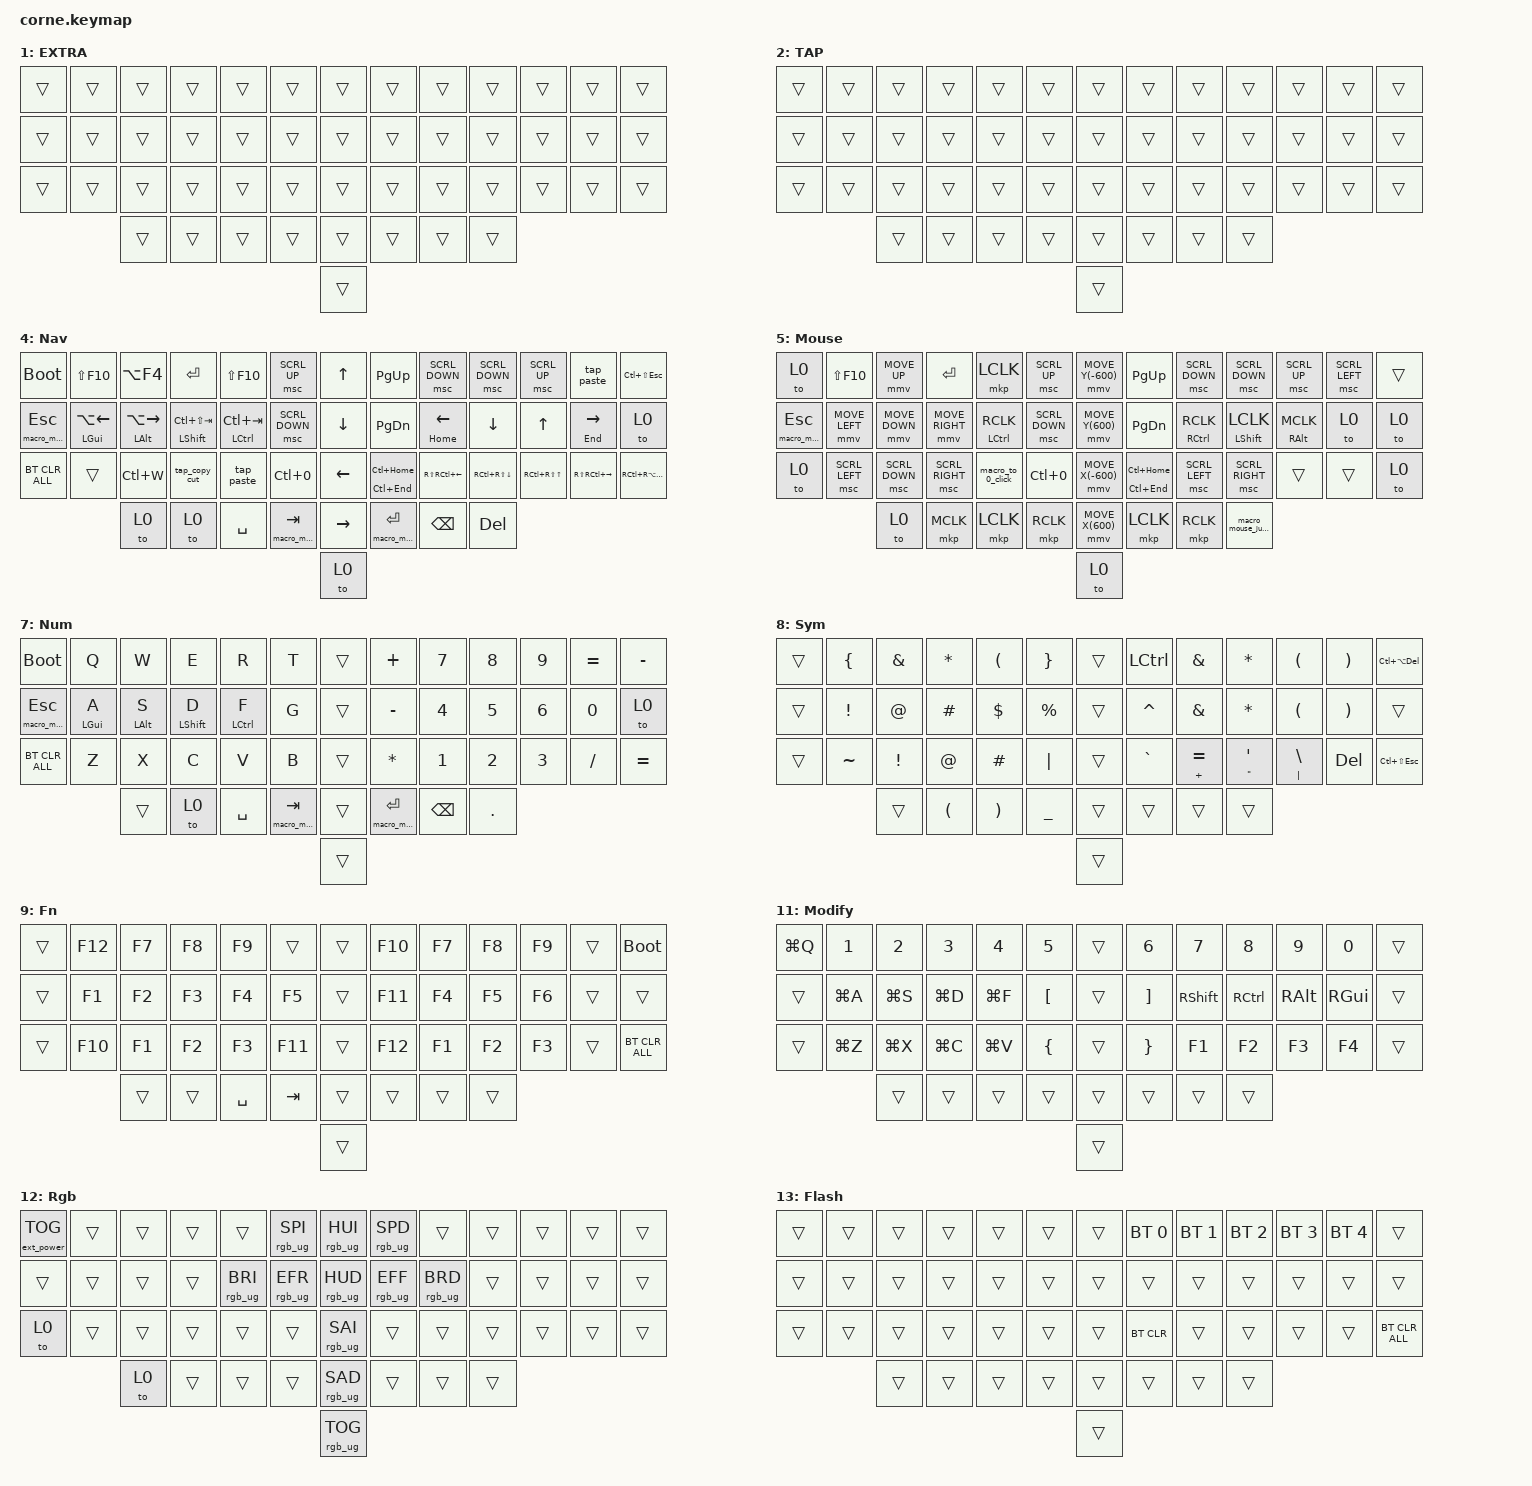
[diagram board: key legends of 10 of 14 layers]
#define ZMK_POINTING_DEFAULT_MOVE_VAL 1200  // 600
#define ZMK_POINTING_DEFAULT_SCRL_VAL 35    // 10

#include <dt-bindings/zmk/outputs.h>
#include <behaviors/num_word.dtsi> // Requires auto-layer module.
#include <input/processors.dtsi>
#include <zephyr/dt-bindings/input/input-event-codes.h>
#include "zmk-helpers/helper.h"
#include <behaviors.dtsi>
#include <dt-bindings/zmk/bt.h>
#include <dt-bindings/zmk/ext_power.h>
#include <dt-bindings/zmk/keys.h>
#include <dt-bindings/zmk/pointing.h>
#include <dt-bindings/zmk/rgb.h>

// Special Aliases

#define ___ &trans
#define MEH     LC(LS(LALT))
#define HYPER   LC(LS(LA(LGUI)))
#define U_RDO   LC(Y)
#define U_PST   LC(V)
#define U_PST_P LS(LC(V))
#define U_CPY   LC(C)
#define U_CUT   LC(X)
#define U_UND   LC(Z)

// Switch program by taskbar position

#define T_1 &kp LC(LG(N1))
#define T_2 &kp LG(LC(N2))
#define T_3 &kp LG(LC(N3))
#define T_4 &kp LG(LC(N4))
#define T_5 &kp LG(LC(N5))
#define T_6 &kp LG(LC(N6))
#define T_7 &kp LG(LC(N7))
#define T_8 &kp LG(LC(N8))
#define T_9 &kp LG(LC(N9))
#define T_0 &kp LG(LC(N0))

// Switch monitor layout

#define M_1 &kp LG(LC(LA(N1)))
#define M_2 &kp LG(LC(LA(N2)))
#define M_3 &kp LG(LC(LA(N3)))
#define M_4 &kp LG(LC(LA(N4)))
#define M_5 &kp LG(LC(LA(N5)))
#define M_6 &kp LG(LC(LA(N6)))
#define M_7 &kp LG(LC(LA(N7)))
#define M_8 &kp LG(LC(LA(N8)))
#define M_9 &kp LG(LC(LA(N9)))
#define M_0 &kp LG(LC(LA(N0)))

/* Global defaults */

#define QUICK_TAP_MS 175

/*



SENSIBLE_LAYER_LIST?

#define DEF 0
#define NAV 1
#define FN 2
#define NUM 3
#define SYS 4
#define MOUSE 5


*/

/ {
    zip_scroll_scaler: zip_scroll_scaler {
        compatible = "zmk,input-processor-scaler";
        #input-processor-cells = <2>;
        type = <INPUT_EV_REL>;
        codes = <INPUT_REL_WHEEL INPUT_REL_HWHEEL>;
        track-remainders;
    };
};

&mmv_input_listener { input-processors = <&zip_xy_scaler 2 1>; };

&msc_input_listener { input-processors = <&zip_scroll_scaler 2 1>; };

&msc {
    acceleration-exponent = <0>;      // 0
    time-to-max-speed-ms = <0>;       // 300
    delay-ms = <0>;                   // 0
};

&mmv {
    time-to-max-speed-ms = <500>;
    acceleration-exponent = <3>;
};

&inc_dec_kp {
    tap-ms = <0>;
    bindings = <&kp>, <&kp>;
};

&sk { quick-release; };

&sl {
    ignore-modifiers;          // allow chording sticky mods & layers
};

&lt {
    flavor = "balanced";
    tapping-term-ms = <200>;
    quick-tap-ms = <QUICK_TAP_MS>;
};

/ {
    macros {
        macro_dot_shift: macro_dot_shift {
            compatible = "zmk,behavior-macro";
            #binding-cells = <0>;
            bindings = <&kp DOT &kp SPACE &sk LSHFT>;
            label = "MACRO_DOT_SHIFT";
        };

        macro_mouse_jump: to_mouse {
            compatible = "zmk,behavior-macro";
            #binding-cells = <0>;
            bindings = <&kp LS(RG(D)) &to 5>;
            label = "TO_MOUSE";
        };

        macro_to_0_click: macro_to_0_click {
            compatible = "zmk,behavior-macro";
            #binding-cells = <0>;
            bindings = <&mkp RCLK &to 0>;
            label = "MACRO_TO_0_CLICK";
        };

        macro_sel_word: macro_sel_word {
            compatible = "zmk,behavior-macro";
            #binding-cells = <0>;
            bindings = <&kp LC(LEFT) &kp LC(LS(RIGHT))>;
            label = "MACRO_SEL_WORD";
        };

        macro_sel_line: macro_sel_line {
            compatible = "zmk,behavior-macro";
            #binding-cells = <0>;
            bindings = <&kp HOME &kp LS(END)>;
            label = "MACRO_SEL_LINE";
        };

        macro_win_sleep: macro_win_sleep {
            compatible = "zmk,behavior-macro";
            #binding-cells = <0>;
            bindings = <&kp LG(X) &kp U &kp S>;
            label = "MACRO_WIN_SLEEP";
            wait-ms = <500>;
            tap-ms = <5>;
        };

        macro_swapper: macro_swapper {
            compatible = "zmk,behavior-macro";
            #binding-cells = <0>;
            bindings =
                <&macro_press>,
                <&kp LALT>,
                <&macro_tap>,
                <&kp TAB>,
                <&macro_release>,
                <&kp LALT>;

            label = "MACRO_SWAPPER";
        };

        double_click: double_click {
            compatible = "zmk,behavior-macro";
            #binding-cells = <0>;
            bindings = <&mkp RCLK &mkp RCLK>;
            label = "DOUBLE_CLICK";
        };

        macro_mouse_jiggle: mouse_jiggle {
            compatible = "zmk,behavior-macro";
            #binding-cells = <0>;
            bindings = <&to 0 &mmv MOVE_UP &mmv MOVE_LEFT &mmv MOVE_DOWN &mmv MOVE_RIGHT>;
            label = "MOUSE_JIGGLE";
        };
    };

    behaviors {
        hml: homerow_mods_left {
            compatible = "zmk,behavior-hold-tap";
            label = "HOMEROW_MODS_LEFT";
            bindings = <&kp>, <&kp>;

            #binding-cells = <2>;
            tapping-term-ms = <175>;
            quick-tap-ms = <150>;
            flavor = "balanced";
            require-prior-idle-ms = <0>;
            hold-trigger-key-positions = <21 22 23 41 20 7 8 33 34 35 36 37 38 25 24 11 12 10 9 44 45 46 14 40 42>;
        };

        hmr: homerow_mods_right {
            compatible = "zmk,behavior-hold-tap";
            label = "HOMEROW_MODS_RIGHT";
            bindings = <&kp>, <&kp>;

            #binding-cells = <2>;
            tapping-term-ms = <175>;
            quick-tap-ms = <150>;
            flavor = "balanced";
            require-prior-idle-ms = <0>;
            hold-trigger-key-positions = <14 15 16 17 0 1 13 26 27 28 29 30 31 5 2 3 4 18 23 45 46 44>;
        };

        ltq: ltq {
            compatible = "zmk,behavior-hold-tap";
            label = "LTQ";
            bindings = <&mo>, <&kp>;

            #binding-cells = <2>;
            tapping-term-ms = <175>;
            quick-tap-ms = <150>;
            flavor = "balanced";
            require-prior-idle-ms = <50>;
            hold-trigger-key-positions = <21 22 23 24 2 15 16 1>;
        };

        as: auto_shift {
            compatible = "zmk,behavior-hold-tap";
            label = "AUTO_SHIFT";
            bindings = <&kp>, <&kp>;

            #binding-cells = <2>;
            tapping-term-ms = <225>;
            quick-tap-ms = <175>;
            flavor = "tap-preferred";
            require-prior-idle-ms = <50>;
        };

        num_word: num_word {
            compatible = "zmk,behavior-auto-layer";
            #binding-cells = <1>;
            continue-list = <BSPC DEL KP_DOT DOT COMMA KP_PLUS PLUS KP_MINUS MINUS KP_MULTIPLY STAR KP_DIVIDE FSLH EQUAL>;
            ignore-numbers;
        };

        smart_num: smart_num {
            compatible = "zmk,behavior-hold-tap";
            label = "SMART_NUM";
            bindings = <&mo>, <&num_word>;

            #binding-cells = <2>;
            tapping-term-ms = <150>;
            flavor = "tap-preferred";
            hold-trigger-key-positions = <41>;
        };

        rgb_encoder: rgb_encoder {
            compatible = "zmk,behavior-sensor-rotate";
            label = "RGB_ENCODER";
            #sensor-binding-cells = <0>;
            bindings = <&rgb_ug RGB_BRI>, <&rgb_ug RGB_BRD>;

            tap-ms = <5>;
        };

        scroll_encoder: scroll_encoder {
            compatible = "zmk,behavior-sensor-rotate";
            #sensor-binding-cells = <0>;
            bindings = <&msc SCRL_UP>, <&msc SCRL_DOWN>;

            tap-ms = <5>;
            label = "scroll_encoder";
        };

        backspace_delete: backspace_delete {
            compatible = "zmk,behavior-mod-morph";
            #binding-cells = <0>;
            bindings = <&kp BACKSPACE>, <&kp DELETE>;

            mods = <(MOD_LSFT|MOD_RSFT)>;
            keep-mods = <(MOD_RSFT)>;
            label = "BACKSPACE_DELETE";
        };

        tap_dot_shift: tap_dot_shift {
            compatible = "zmk,behavior-tap-dance";
            label = "tap_dot_shift";
            #binding-cells = <0>;
            bindings = <&kp DOT>, <&macro_dot_shift>;

            tapping-term-ms = <250>;
        };

        c_tap_copy_cut: c_tap_copy_cut {
            compatible = "zmk,behavior-tap-dance";
            label = "C_TAP_COPY_CUT";
            #binding-cells = <0>;
            tapping-term-ms = <250>;
            bindings = <&kp C>, <&kp LC(C)>, <&kp LC(X)>;
        };

        sk_qr: sk_qr {
            compatible = "zmk,behavior-sticky-key";
            label = "SK_QR";
            bindings = <&sk>;
            #binding-cells = <1>;
            quick-release;
            release-after-ms = <900>;
        };

        morph_column: morph_column {
            compatible = "zmk,behavior-mod-morph";
            label = "MORPH_COLUMN";
            bindings = <&kp COLON>, <&kp SEMICOLON>;

            #binding-cells = <0>;
            mods = <(MOD_LSFT)>;
            keep-mods = <(MOD_LSFT)>;
        };

        ltq_mouse_column: ltq_mouse_column {
            compatible = "zmk,behavior-hold-tap";
            label = "LTQ_MOUSE_COLUMN";
            bindings = <&mo>, <&morph_column>;

            #binding-cells = <2>;
            flavor = "balanced";
            tapping-term-ms = <175>;
            quick-tap-ms = <150>;
            require-prior-idle-ms = <50>;
            hold-trigger-key-positions = <15 14 2 16 4 17 41 42 44 45 20>;
        };

        tap_quote_to_nav_mouse: tap_quote_to_nav_mouse {
            compatible = "zmk,behavior-tap-dance";
            label = "TAP_QUOTE_TO_NAV_MOUSE";
            #binding-cells = <0>;
            bindings = <&kp SQT>, <&to 4>, <&to 5>;

            tapping-term-ms = <150>;
        };

        dot_shift: dot_shift {
            compatible = "zmk,behavior-hold-tap";
            label = "DOT_SHIFT";
            bindings = <&macro_dot_shift>, <&kp>;

            #binding-cells = <2>;
            tapping-term-ms = <250>;
            quick-tap-ms = <200>;
            flavor = "tap-preferred";
            require-prior-idle-ms = <150>;
            hold-trigger-on-release;
        };

        hmr_clk: hmr_clk {
            compatible = "zmk,behavior-hold-tap";
            label = "HMR_CLK";
            bindings = <&hmr>, <&mkp>;

            #binding-cells = <2>;
            tapping-term-ms = <250>;
            quick-tap-ms = <200>;
            flavor = "tap-preferred";
            require-prior-idle-ms = <150>;
        };

        v_tap_paste: v_tap_paste {
            compatible = "zmk,behavior-tap-dance";
            label = "V_TAP_PASTE";
            #binding-cells = <0>;
            tapping-term-ms = <250>;
            bindings = <&kp V>, <&kp LC(V)>, <&kp LC(LS(V))>;
        };

        tap_paste: tap_paste {
            compatible = "zmk,behavior-tap-dance";
            label = "TAP_PASTE";
            #binding-cells = <0>;
            tapping-term-ms = <250>;
            bindings = <&kp LC(V)>, <&kp LC(LS(V))>;
        };

        tap_copy_cut: tap_copy_cut {
            compatible = "zmk,behavior-tap-dance";
            label = "TAP_COPY_CUT";
            #binding-cells = <0>;
            tapping-term-ms = <250>;
            bindings = <&kp LC(C)>, <&kp LC(X)>;
        };

        tap_dot_shift_capsword: tap_dot_shift_capsword {
            compatible = "zmk,behavior-tap-dance";
            label = "TAP_DOT_SHIFT_CAPSWORD";
            #binding-cells = <0>;
            tapping-term-ms = <250>;
            bindings = <&kp DOT>, <&macro_dot_shift>, <&caps_word>;
        };

        tap_key_repeat_lt: tap_key_repeat_lt {
            compatible = "zmk,behavior-hold-tap";
            label = "TAP_KEY_REPEAT_LT";
            #binding-cells = <2>;
            tapping-term-ms = <175>;
            quick-tap-ms = <150>;
            flavor = "balanced";
            require-prior-idle-ms = <50>;
            bindings = <&lt>, <&key_repeat>;
        };

        mod_to: mod_to {
            compatible = "zmk,behavior-hold-tap";
            label = "MOD_TO";
            bindings = <&to>, <&kp>;

            #binding-cells = <2>;
            tapping-term-ms = <225>;
            quick-tap-ms = <175>;
            flavor = "tap-preferred";
            require-prior-idle-ms = <50>;
        };

        mod_to0_mouse_jiggle: mod_to0_mouse_jiggle {
            compatible = "zmk,behavior-hold-tap";
            label = "MOD_TO0_MOUSE_JIGGLE";
            bindings = <&macro_mouse_jiggle>, <&kp>;

            #binding-cells = <2>;
            tapping-term-ms = <225>;
            quick-tap-ms = <175>;
            flavor = "tap-preferred";
            require-prior-idle-ms = <50>;
        };

        tap_flip_komorebic: tap_flip_komorebic {
            compatible = "zmk,behavior-tap-dance";
            label = "TAP_FLIP_KOMOREBIC";
            #binding-cells = <0>;
            tapping-term-ms = <200>;
            bindings = <&kp RS(RA(F17))>, <&kp RA(RS(F18))>, <&none>;
        };
    };

    combos {
        compatible = "zmk,combos";

        tap_copy_cut {
            bindings = <&tap_copy_cut>;
            key-positions = <28 29>;
        };

        tap_paste {
            bindings = <&tap_paste>;
            key-positions = <29 30>;
        };

        Enter_v2 {
            bindings = <&kp RET>;
            key-positions = <17 3>;
        };

        Undo {
            bindings = <&kp LC(Z)>;
            key-positions = <35 34>;
        };

        Redo {
            bindings = <&kp LS(LC(Z))>;
            key-positions = <35 36>;
        };

        ctrl_space {
            bindings = <&kp LC(SPACE)>;
            key-positions = <41 17>;
            timeout-ms = <30>;
            require-prior-idle-ms = <30>;
        };

        to_mouse {
            bindings = <&to 5>;
            key-positions = <24 23>;
        };

        f21 {
            bindings = <&kp F21>;
            key-positions = <23 22>;
        };

        macro_dot_shift {
            bindings = <&tap_dot_shift_capsword>;
            key-positions = <16 41>;
            layers = <0>;
        };

        to_0v2 {
            bindings = <&to 0>;
            key-positions = <42 41>;
        };

        to_0v1 {
            bindings = <&to 0>;
            key-positions = <18 17>;
        };

        to_ov3 {
            bindings = <&to 0>;
            key-positions = <44 45>;
        };

        Select_all {
            bindings = <&kp LC(A)>;
            key-positions = <27 28>;
        };
    };

    #define KEYS_L LT0 LT1 LT2 LT3 LT4 LT5 LM0 LM1 LM2 LM3 LM4 LM5 LB0 LB1 LB2 LB3 LB4 LB5  // left hand
#define KEYS_R RT0 RT1 RT2 RT3 RT4 RT5 RM0 RM1 RM2 RM3 RM4 RM5 RB0 RB1 RB2 RB3 RB4 RB5  // right hand
#define THUMBS LH2 LH1 LH0 RH0 RH1 RH2   // thumbs
    /*                42 KEY MATRIX with ENCODER and JOYSTICK / LAYOUT MAPPING

  ╭──────────────────────────────╮              ╭─────╮      ╭──────────────────────────────╮
  │ LT5  LT4  LT3  LT2  LT1  LT0 │          ╭───╯ JS0 ╰───╮  │ RT0  RT1  RT2  RT3  RT4  RT5 │
  │ LM5  LM4  LM3  LM2  LM1  LM0 │ ╭─────╮  │ JS1 JS2 JS3 │  │ RM0  RM1  RM2  RM3  RM4  RM5 │
  │ LB5  LB4  LB3  LB2  LB1  LB0 │ │ LEC │  ╰───╮ JS4 ╭───╯  │ RB0  RB1  RB2  RB3  RB4  RB5 │
  ╰──────────────╮ LH2  LH1  LH0 │ ╰─────╯      ╰─────╯      │ RH0  RH1  RH2 ╭──────────────╯
                 ╰───────────────╯                           ╰───────────────╯


#define MAKE_HRM(NAME, HOLD, TAP, TRIGGER_POS)                                 \
  ZMK_HOLD_TAP(

    NAME,
    bindings = <HOLD>, <TAP>;

    flavor = "balanced";
    tapping-term-ms = <280>;
    quick-tap-ms = <QUICK_TAP_MS>;
    require-prior-idle-ms = <150>;
    hold-trigger-on-release;
    hold-trigger-key-positions = <TRIGGER_POS>;

    )

MAKE_HRM(hmlx, &kp, &kp, KEYS_R THUMBS) // Left-hand HRMs.
    MAKE_HRM(hmrx, &kp, &kp, KEYS_L THUMBS) // Right-hand HRMs.

// Hack: Make HRM combos tap-only (cf, ZMK issue #544).
#define ZMK_COMBO_8(NAME, TAP, POS, LAYERS, COMBO_MS, IDLE_MS, HOLD, SIDE)     \
  MAKE_HRM(hm_combo_##NAME, &kp, TAP, SIDE THUMBS)                             \
  ZMK_COMBO_6(NAME, &hm_combo_##NAME HOLD 0, POS, LAYERS, COMBO_MS, IDLE_MS)


// Tap: num-word | double-tap: sticky num-layer | Hold: num-layer.
#define SMART_NUM &smart_num NUM 0
ZMK_HOLD_TAP(

    smart_num,
    bindings = <&mo>, <&num_dance>;

    flavor = "balanced";
    tapping-term-ms = <200>;
    quick-tap-ms = <QUICK_TAP_MS>;

    )
ZMK_TAP_DANCE(

    num_dance,
    bindings = <&num_word NUM>, <&sl NUM>;

    tapping-term-ms = <200>;

    )

*/

    keymap {
        compatible = "zmk,keymap";

        BASE {
            bindings = <
&ltq 12 GRAVE                   &as LS(F10) Q  &kp W            &as RET E          &as LS(F10) R        &kp T                  &kp UP_ARROW    &as PAGE_UP Y    &kp U             &kp I                   &kp O                    &kp P        &as RC(MINUS) MINUS
&mod_to0_mouse_jiggle 0 ESCAPE  &ltq 4 A       &hml LEFT_ALT S  &hml LEFT_SHIFT D  &hml LCTRL F         &hml LEFT_GUI G        &kp DOWN_ARROW  &as PAGE_DOWN H  &hmr RCTRL J      &hmr LEFT_SHIFT K       &hmr RIGHT_ALT L         &ltq 5 SEMI  &tap_quote_to_nav_mouse
&ltq 3 LA(TAB)                  &kp Z          &kp X            &kp C              &as LC(LA(LS(V))) V  &as LS(LA(LC(V))) B    &kp LEFT        &kp N            &kp M             &kp COMMA               &tap_dot_shift_capsword  &kp FSLH     &as RC(EQUAL) EQUAL
                                               &ltq 6 C_MUTE    &smart_num 7 7     &ltq 10 SPACE        &ltq 4 TAB             &kp RIGHT       &ltq 5 RET       &ltq 6 BACKSPACE  &tap_key_repeat_lt 9 9
                                                                                                                               &to 5
            >;

            label = "BASE";
            sensor-bindings = <&inc_dec_kp UP DOWN>;
        };

        EXTRA {
            bindings = <
&trans  &trans  &trans  &trans  &trans  &trans    &trans  &trans  &trans  &trans  &trans  &trans  &trans
&trans  &trans  &trans  &trans  &trans  &trans    &trans  &trans  &trans  &trans  &trans  &trans  &trans
&trans  &trans  &trans  &trans  &trans  &trans    &trans  &trans  &trans  &trans  &trans  &trans  &trans
                &trans  &trans  &trans  &trans    &trans  &trans  &trans  &trans
                                                  &trans
            >;

            label = "EXTRA";
        };

        TAP {
            bindings = <
&trans  &trans  &trans  &trans  &trans  &trans    &trans  &trans  &trans  &trans  &trans  &trans  &trans
&trans  &trans  &trans  &trans  &trans  &trans    &trans  &trans  &trans  &trans  &trans  &trans  &trans
&trans  &trans  &trans  &trans  &trans  &trans    &trans  &trans  &trans  &trans  &trans  &trans  &trans
                &trans  &trans  &trans  &trans    &trans  &trans  &trans  &trans
                                                  &trans
            >;

            label = "TAP";
        };

        BUTTON {
            bindings = <
&trans  &kp LS(LG(LC(LA(Q))))  &kp LA(F4)  &kp LG(LC(LA(E)))         &kp LC(F24)              &kp LS(LG(LC(LA(T))))             &trans  &trans             &trans              &trans             &trans      &kp LG(LC(LA(P)))    &kp RC(RA(DEL))
&trans  &kp LG(LC(LA(T)))      &kp F24     &kp LS(F24)               &kp LG(LC(LA(F)))        &kp LG(LC(LA(G)))                 &trans  &kp LG(LC(LA(H)))  &kp LG(LEFT_ARROW)  &kp LG(DOWN)       &kp LG(UP)  &kp LG(RIGHT_ARROW)  &trans
&trans  &macro_win_sleep       &trans      &kp LG(LC(LA(C)))         &kp LS(LC(V))            &kp LS(LG(LC(LA(B))))             &trans  &trans             &trans              &trans             &trans      &trans               &kp RS(RC(ESC))
                               &trans      &as LC(LA(LS(M))) C_PREV  &as C_MUTE C_PLAY_PAUSE  &as LS(LG(LA(LC(F11)))) C_NEXT    &trans  &kp F24            &kp RS(F24)         &kp LG(LC(LA(H)))
                                                                                                                                &trans
            >;

            label = "BUTTON";
            sensor-bindings = <&inc_dec_kp LC(LS(TAB)) LC(LS(TAB))>;
        };

        NAV {
            bindings = <
&bootloader                  &kp LS(F10)         &kp LA(F4)           &kp ENTER                    &kp LS(F10)         &msc SCRL_UP                   &kp UP_ARROW    &kp PG_UP                    &msc SCRL_DOWN    &msc SCRL_DOWN    &msc SCRL_UP    &tap_paste         &kp LC(LS(ESC))
&mod_to0_mouse_jiggle 0 ESC  &hml LGUI LA(LEFT)  &hml LALT LA(RIGHT)  &hml LEFT_SHIFT LC(LS(TAB))  &hml LCTRL LC(TAB)  &msc SCRL_DOWN                 &kp DOWN_ARROW  &kp PG_DN                    &as HOME LEFT     &kp DOWN_ARROW    &kp UP          &as END RIGHT      &to 0
&bt BT_CLR_ALL               &trans              &kp LC(W)            &tap_copy_cut                &tap_paste          &kp LC(N0)                     &kp LEFT        &as LC(END) LC(HOME)         &kp RS(RC(LEFT))  &kp RC(RS(DOWN))  &kp RC(RS(UP))  &kp RS(RC(RIGHT))  &kp RC(RA(DEL))
                                                 &to 0                &to 0                        &kp SPACE           &mod_to0_mouse_jiggle 0 TAB    &kp RIGHT       &mod_to0_mouse_jiggle 0 RET  &kp BACKSPACE     &kp DEL
                                                                                                                                                      &to 0
            >;

            sensor-bindings = <&inc_dec_kp UP_ARROW DOWN_ARROW>;
            label = "Nav";
        };

        Mouse {
            bindings = <
&to 0                        &kp LS(F10)     &mmv MOVE_UP    &kp RET          &mkp LCLK            &msc SCRL_UP      &mmv MOVE_Y(-600)  &kp PAGE_UP           &msc SCRL_DOWN       &msc SCRL_DOWN       &msc SCRL_UP        &msc SCRL_LEFT  &trans
&mod_to0_mouse_jiggle 0 ESC  &mmv MOVE_LEFT  &mmv MOVE_DOWN  &mmv MOVE_RIGHT  &hmr_clk LCTRL RCLK  &msc SCRL_DOWN    &mmv MOVE_Y(600)   &kp PAGE_DOWN         &hmr_clk RCTRL RCLK  &hmr_clk LSHFT LCLK  &hmr_clk RALT MCLK  &to 0           &to 0
&to 0                        &msc SCRL_LEFT  &msc SCRL_DOWN  &msc SCRL_RIGHT  &macro_to_0_click    &kp LC(N0)        &mmv MOVE_X(-600)  &as LC(END) LC(HOME)  &msc SCRL_LEFT       &msc SCRL_RIGHT      &trans              &trans          &to 0
                                             &to 0           &mkp MCLK        &mkp LCLK            &mkp RCLK         &mmv MOVE_X(600)   &mkp LCLK             &mkp RCLK            &macro_mouse_jump
                                                                                                                     &to 0
            >;

            label = "Mouse";
            sensor-bindings = <&inc_dec_kp UP_ARROW DOWN_ARROW>;
        };

        SWAP {
            bindings = <
&bootloader                  &trans                &kp LA(F4)            &trans                  &trans                &trans                            &kp LG(UP)     &kp LG(LC(LA(N1)))  &kp LG(LC(LA(N2)))       &kp LG(LC(LA(N3)))              &kp LG(LC(LA(N4)))  &kp LG(LC(LA(N5)))  &bootloader
&mod_to0_mouse_jiggle 0 ESC  &kp LC(LG(NUMBER_1))  &kp LC(LG(NUMBER_2))  &kp LC(LG(NUMBER_3))    &kp LC(LG(NUMBER_4))  &kp LC(LG(N5))                    &kp LG(DOWN)   &kp LC(LG(N6))      &kp LC(LG(N7))           &kp LG(LC(N8))                  &kp LC(LG(N9))      &kp LC(LG(N0))      &soft_off
&bt BT_CLR_ALL               &kp LC(LG(N0))        &kp LC(LG(N9))        &kp LC(LG(N8))          &kp LC(LG(N7))        &kp LC(LG(N6))                    &kp LG(LEFT)   &bt BT_NXT          &bt BT_PRV               &trans                          &trans              &trans              &bt BT_CLR_ALL
                                                   &trans                &kp LS(LA(LC(LG(F9))))  &ltq 10 LA(F4)        &mod_to0_mouse_jiggle 0 LA(F4)    &kp LG(RIGHT)  &as RG(TAB) C_PREV  &as C_MUTE C_PLAY_PAUSE  &as RS(RA(RC(RG(F11)))) C_NEXT
                                                                                                                                                         &trans
            >;

            label = "Swap";
            sensor-bindings = <&inc_dec_kp C_VOLUME_UP C_VOLUME_DOWN>;
        };

        NUM {
            bindings = <
&bootloader                  &kp Q        &kp W        &kp E         &kp R         &kp T                          &trans  &kp PLUS                     &kp N7         &kp N8   &kp N9  &kp EQUAL  &kp MINUS
&mod_to0_mouse_jiggle 0 ESC  &hml LGUI A  &hml LALT S  &hml LSHFT D  &hml LCTRL F  &kp G                          &trans  &kp MINUS                    &kp N4         &kp N5   &kp N6  &kp N0     &to 0
&bt BT_CLR_ALL               &kp Z        &kp X        &kp C         &kp V         &kp B                          &trans  &kp ASTRK                    &kp N1         &kp N2   &kp N3  &kp FSLH   &kp EQUAL
                                          &trans       &to 0         &kp SPACE     &mod_to0_mouse_jiggle 0 TAB    &trans  &mod_to0_mouse_jiggle 0 RET  &kp BACKSPACE  &kp DOT
                                                                                                                  &trans
            >;

            label = "Num";
        };

        Symbol {
            bindings = <
&trans  &kp LEFT_BRACE   &kp AMPERSAND  &kp ASTERISK          &kp LEFT_PARENTHESIS   &kp RIGHT_BRACE    &trans  &kp LCTRL  &kp AMPERSAND   &kp ASTERISK           &kp LEFT_PARENTHESIS  &kp RIGHT_PARENTHESIS  &kp LC(LA(DELETE))
&trans  &kp EXCLAMATION  &kp AT_SIGN    &kp HASH              &kp DOLLAR             &kp PERCENT        &trans  &kp CARET  &kp AMPERSAND   &kp ASTERISK           &kp LEFT_PARENTHESIS  &kp RIGHT_PARENTHESIS  &trans
&trans  &kp TILDE        &kp EXCL       &kp AT_SIGN           &kp POUND              &kp PIPE           &trans  &kp GRAVE  &as PLUS EQUAL  &as DOUBLE_QUOTES SQT  &as PIPE BACKSLASH    &kp DELETE             &kp LC(LS(ESCAPE))
                         &trans         &kp LEFT_PARENTHESIS  &kp RIGHT_PARENTHESIS  &kp UNDER          &trans  &trans     &trans          &trans
                                                                                                        &trans
            >;

            label = "Sym";
            sensor-bindings = <&inc_dec_kp C_VOLUME_UP C_VOLUME_DOWN>;
        };

        Fn {
            bindings = <
&trans  &kp F12  &kp F7  &kp F8  &kp F9     &trans     &trans  &kp F10  &kp F7  &kp F8  &kp F9  &trans  &bootloader
&trans  &kp F1   &kp F2  &kp F3  &kp F4     &kp F5     &trans  &kp F11  &kp F4  &kp F5  &kp F6  &trans  &trans
&trans  &kp F10  &kp F1  &kp F2  &kp F3     &kp F11    &trans  &kp F12  &kp F1  &kp F2  &kp F3  &trans  &bt BT_CLR_ALL
                 &trans  &trans  &kp SPACE  &kp TAB    &trans  &trans   &trans  &trans
                                                       &trans
            >;

            label = "Fn";
        };

        L10 {
            bindings = <
&sys_reset                   &trans                 &kp LA(F15)          &trans                    &kp LC(LA(LS(F20)))      &kp F21                           &kp LA(F15)  &trans           &kp RC(RA(F13))  &kp RC(RA(F14))      &kp RC(RA(F15))  &kp RC(RA(F16))  &kp LC(LA(DEL))
&mod_to0_mouse_jiggle 0 ESC  &hml LEFT_WIN LA(F13)  &hml LALT LA(F14)    &hml LSHFT LA(F16)        &hml LCTRL LS(F16)       &kp LS(F20)                       &kp LA(F14)  &kp LG(TAB)      &hmr RCTRL F13   &hmr RSHFT F14       &hmr RALT F15    &hmr LGUI F16    &trans
&mod_to0_mouse_jiggle 0 Z    &trans                 &kp LC(LS(LA(F17)))  &trans                    &kp LC(LS(V))            &trans                            &kp LA(F13)  &trans           &kp RS(RA(F17))  &kp RS(RA(F18))      &kp F19          &kp F20          &kp RS(RC(ESC))
                                                    &trans               &as LC(LA(LS(M))) C_PREV  &as C_MUTE C_PLAY_PAUSE  &as LS(LA(LC(LG(F11)))) C_NEXT    &kp LA(F16)  &as RG(TAB) F21  &ltq 6 RA(F4)    &tap_flip_komorebic
                                                                                                                                                              &trans
            >;

            label = "L10";
        };

        Modify {
            bindings = <
&kp LG(Q)  &kp NUMBER_1  &kp NUMBER_2  &kp NUMBER_3  &kp NUMBER_4  &kp NUMBER_5        &trans  &kp NUMBER_6       &kp NUMBER_7     &kp NUMBER_8       &kp NUMBER_9   &kp NUMBER_0   &trans
&trans     &kp LG(A)     &kp LG(S)     &kp LG(D)     &kp LG(F)     &kp LEFT_BRACKET    &trans  &kp RIGHT_BRACKET  &kp RIGHT_SHIFT  &kp RIGHT_CONTROL  &kp RIGHT_ALT  &kp RIGHT_GUI  &trans
&trans     &kp LG(Z)     &kp LG(X)     &kp LG(C)     &kp LG(V)     &kp LEFT_BRACE      &trans  &kp RIGHT_BRACE    &kp F1           &kp F2             &kp F3         &kp F4         &trans
                         &trans        &trans        &trans        &trans              &trans  &trans             &trans           &trans
                                                                                       &trans
            >;

            label = "Modify";
        };

        Rgb {
            bindings = <
&ext_power EP_TOG  &trans  &trans  &trans  &trans           &rgb_ug RGB_SPI    &rgb_ug RGB_HUI  &rgb_ug RGB_SPD  &trans           &trans  &trans  &trans  &trans
&trans             &trans  &trans  &trans  &rgb_ug RGB_BRI  &rgb_ug RGB_EFR    &rgb_ug RGB_HUD  &rgb_ug RGB_EFF  &rgb_ug RGB_BRD  &trans  &trans  &trans  &trans
&to 0              &trans  &trans  &trans  &trans           &trans             &rgb_ug RGB_SAI  &trans           &trans           &trans  &trans  &trans  &trans
                           &to 0   &trans  &trans           &trans             &rgb_ug RGB_SAD  &trans           &trans           &trans
                                                                               &rgb_ug RGB_TOG
            >;

            label = "Rgb";
            sensor-bindings = <&rgb_encoder &scroll_encoder>;
        };

        Flash {
            bindings = <
&trans  &trans  &trans  &trans  &trans  &trans    &trans  &bt BT_SEL 0  &bt BT_SEL 1  &bt BT_SEL 2  &bt BT_SEL 3  &bt BT_SEL 4  &trans
&trans  &trans  &trans  &trans  &trans  &trans    &trans  &trans        &trans        &trans        &trans        &trans        &trans
&trans  &trans  &trans  &trans  &trans  &trans    &trans  &bt BT_CLR    &trans        &trans        &trans        &trans        &bt BT_CLR_ALL
                &trans  &trans  &trans  &trans    &trans  &trans        &trans        &trans
                                                  &trans
            >;

            label = "Flash";
        };
    };

    conditional_layers { compatible = "zmk,conditional-layers"; };
};
